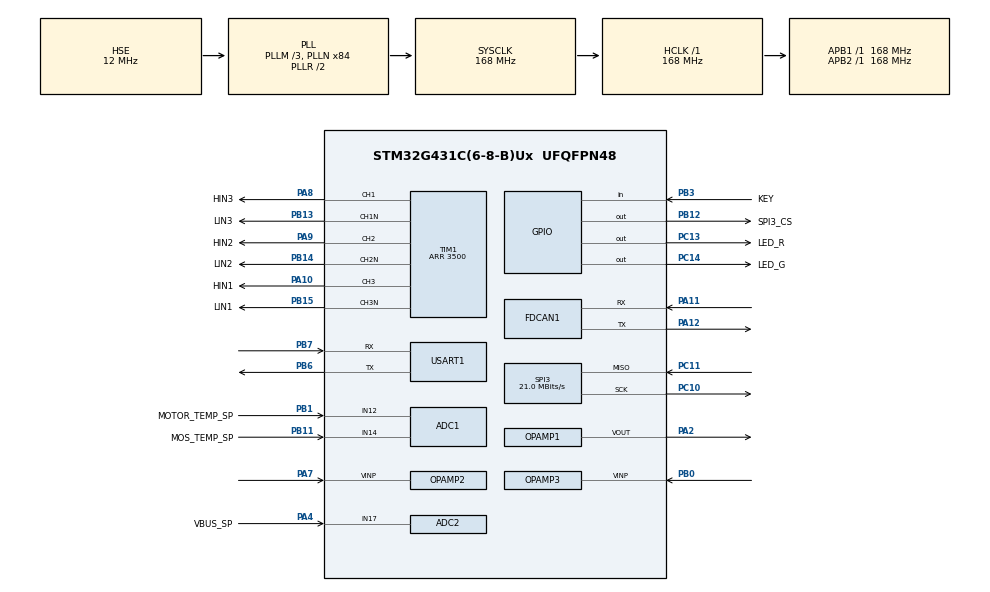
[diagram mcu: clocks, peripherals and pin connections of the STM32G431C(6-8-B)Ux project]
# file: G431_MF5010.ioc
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ADC1.Channel-0\#ChannelRegularConversion=ADC_CHANNEL_12
ADC1.Channel-1\#ChannelRegularConversion=ADC_CHANNEL_14
ADC1.NbrOfConversion=2
ADC1.NbrOfConversionFlag=1
ADC1.OffsetNumber-0\#ChannelRegularConversion=ADC_OFFSET_NONE
ADC1.OffsetNumber-1\#ChannelRegularConversion=ADC_OFFSET_NONE
ADC1.Rank-0\#ChannelRegularConversion=1
ADC1.Rank-1\#ChannelRegularConversion=2
ADC1.SamplingTime-0\#ChannelRegularConversion=ADC_SAMPLETIME_640CYCLES_5
ADC1.SamplingTime-1\#ChannelRegularConversion=ADC_SAMPLETIME_640CYCLES_5
ADC1.master=1
ADC2.ClockPrescaler=ADC_CLOCK_SYNC_PCLK_DIV4
ADC2.ContinuousConvMode=DISABLE
ADC2.EnableInjectedConversion=ENABLE
ADC2.EnableRegularConversion=DISABLE
ADC2.ExternalTrigInjecConv=ADC_EXTERNALTRIGINJEC_T1_CC4
ADC2.InjNumberOfConversion=3
ADC2.InjectedChannel-1\#ChannelInjectedConversion=ADC_CHANNEL_VOPAMP2
ADC2.InjectedChannel-2\#ChannelInjectedConversion=ADC_CHANNEL_VOPAMP3_ADC2
ADC2.InjectedChannel-3\#ChannelInjectedConversion=ADC_CHANNEL_17
ADC2.InjectedOffsetNumber-1\#ChannelInjectedConversion=ADC_OFFSET_NONE
ADC2.InjectedOffsetNumber-2\#ChannelInjectedConversion=ADC_OFFSET_NONE
ADC2.InjectedOffsetNumber-3\#ChannelInjectedConversion=ADC_OFFSET_NONE
ADC2.InjectedRank-1\#ChannelInjectedConversion=1
ADC2.InjectedRank-2\#ChannelInjectedConversion=2
ADC2.InjectedRank-3\#ChannelInjectedConversion=3
ADC2.InjectedSamplingTime-1\#ChannelInjectedConversion=ADC_SAMPLETIME_6CYCLES_5
ADC2.InjectedSamplingTime-2\#ChannelInjectedConversion=ADC_SAMPLETIME_6CYCLES_5
ADC2.InjectedSamplingTime-3\#ChannelInjectedConversion=ADC_SAMPLETIME_6CYCLES_5
Dma.ADC1.0.Direction=DMA_PERIPH_TO_MEMORY
Dma.ADC1.0.EventEnable=DISABLE
Dma.ADC1.0.Instance=DMA1_Channel1
Dma.ADC1.0.MemDataAlignment=DMA_MDATAALIGN_HALFWORD
Dma.ADC1.0.MemInc=DMA_MINC_ENABLE
Dma.ADC1.0.Mode=DMA_CIRCULAR
Dma.ADC1.0.PeriphDataAlignment=DMA_PDATAALIGN_HALFWORD
Dma.ADC1.0.PeriphInc=DMA_PINC_DISABLE
Dma.ADC1.0.Polarity=HAL_DMAMUX_REQ_GEN_RISING
Dma.ADC1.0.Priority=DMA_PRIORITY_LOW
Dma.ADC1.0.RequestNumber=1
Dma.ADC1.0.SignalID=NONE
Dma.ADC1.0.SyncEnable=DISABLE
Dma.ADC1.0.SyncPolarity=HAL_DMAMUX_SYNC_NO_EVENT
Dma.ADC1.0.SyncRequestNumber=1
Dma.ADC1.0.SyncSignalID=NONE
Dma.Request0=ADC1
FDCAN1.AutoRetransmission=DISABLE
FDCAN1.CalculateBaudRateNominal=1000000
FDCAN1.CalculateTimeBitNominal=1000
FDCAN1.CalculateTimeQuantumNominal=35.714285714285715
FDCAN1.DataPrescaler=6
FDCAN1.DataSyncJumpWidth=7
FDCAN1.DataTimeSeg1=20
FDCAN1.DataTimeSeg2=7
FDCAN1.ExtFiltersNbr=0
FDCAN1.NominalPrescaler=6
FDCAN1.NominalSyncJumpWidth=7
FDCAN1.NominalTimeSeg1=20
FDCAN1.NominalTimeSeg2=7
FDCAN1.StdFiltersNbr=1
Mcu.Family=STM32G4
Mcu.Name=STM32G431C(6-8-B)Ux
Mcu.Package=UFQFPN48
NVIC.ADC1_2_IRQn=true\:1\:0\:true\:false\:true\:true\:true\:true
NVIC.DMA1_Channel1_IRQn=true\:0\:0\:true\:false\:true\:false\:true\:true
NVIC.FDCAN1_IT0_IRQn=true\:0\:0\:true\:false\:true\:true\:true\:true
NVIC.PriorityGroup=NVIC_PRIORITYGROUP_4
NVIC.TIM4_IRQn=true\:0\:0\:true\:false\:true\:true\:true\:true
NVIC.TIM7_IRQn=true\:0\:0\:false\:false\:true\:true\:true\:true
NVIC.USART1_IRQn=true\:0\:0\:false\:false\:true\:true\:true\:true
OPAMP1.PowerMode=OPAMP_POWERMODE_HIGHSPEED
OPAMP2.PgaGain=OPAMP_PGA_GAIN_16_OR_MINUS_15
OPAMP2.PowerMode=OPAMP_POWERMODE_HIGHSPEED
OPAMP3.PgaGain=OPAMP_PGA_GAIN_16_OR_MINUS_15
OPAMP3.PowerMode=OPAMP_POWERMODE_HIGHSPEED
PA10.GPIO_Label=HIN1
PA10.Signal=S_TIM1_CH3
PA11.Mode=FDCAN_Activate
PA11.Signal=FDCAN1_RX
PA12.Mode=FDCAN_Activate
PA12.Signal=FDCAN1_TX
PA13.Mode=Serial_Wire
PA13.Signal=SYS_JTMS-SWDIO
PA14.Mode=Serial_Wire
PA14.Signal=SYS_JTCK-SWCLK
PA2.Mode=Follower-DAC_OUT2-INP
PA2.Signal=OPAMP1_VOUT
PA4.GPIO_Label=VBUS_SP
PA4.Mode=IN17-Single-Ended
PA4.Signal=ADC2_IN17
PA7.Mode=PGA_Internally_Connected
PA7.Signal=OPAMP2_VINP
PA8.GPIO_Label=HIN3
PA8.Signal=S_TIM1_CH1
PA9.GPIO_Label=HIN2
PA9.Signal=S_TIM1_CH2
PB0.Mode=PGA_Internally_Connected
PB0.Signal=OPAMP3_VINP
PB1.GPIO_Label=MOTOR_TEMP_SP
PB1.Mode=IN12-Single-Ended
PB1.Signal=ADC1_IN12
PB11.GPIO_Label=MOS_TEMP_SP
PB11.Mode=IN14-Single-Ended
PB11.Signal=ADC1_IN14
PB12.GPIO_Label=SPI3_CS
PB12.GPIO_ModeDefaultOutputPP=GPIO_MODE_OUTPUT_PP
PB12.GPIO_PuPd=GPIO_PULLUP
PB12.GPIO_Speed=GPIO_SPEED_FREQ_VERY_HIGH
PB12.PinState=GPIO_PIN_SET
PB12.Signal=GPIO_Output
PB13.GPIO_Label=LIN3
PB13.Mode=PWM Generation1 CH1 CH1N
PB13.Signal=TIM1_CH1N
PB14.GPIO_Label=LIN2
PB14.Mode=PWM Generation2 CH2 CH2N
PB14.Signal=TIM1_CH2N
PB15.GPIO_Label=LIN1
PB15.Mode=PWM Generation3 CH3 CH3N
PB15.Signal=TIM1_CH3N
PB3.GPIO_Label=KEY
PB3.GPIO_PuPd=GPIO_PULLUP
PB3.Signal=GPIO_Input
PB6.Mode=Asynchronous
PB6.Signal=USART1_TX
PB7.Mode=Asynchronous
PB7.Signal=USART1_RX
PC10.GPIO_PuPd=GPIO_PULLUP
PC10.GPIO_Speed=GPIO_SPEED_FREQ_VERY_HIGH
PC10.Mode=RX_Only_Simplex_Unidirect_Master
PC10.Signal=SPI3_SCK
PC11.GPIO_PuPd=GPIO_PULLUP
PC11.GPIO_Speed=GPIO_SPEED_FREQ_VERY_HIGH
PC11.Mode=RX_Only_Simplex_Unidirect_Master
PC11.Signal=SPI3_MISO
PC13.GPIO_Label=LED_R
PC13.Signal=GPIO_Output
PC14-OSC32_IN.GPIO_Label=LED_G
PC14-OSC32_IN.Signal=GPIO_Output
PF0-OSC_IN.Mode=HSE-External-Oscillator
PF0-OSC_IN.Signal=RCC_OSC_IN
PF1-OSC_OUT.Mode=HSE-External-Oscillator
PF1-OSC_OUT.Signal=RCC_OSC_OUT
ProjectManager.HeapSize=0x200
ProjectManager.StackSize=0x400
ProjectManager.TargetToolchain=STM32CubeIDE
RCC.ADC12Freq_Value=168000000
RCC.AHBFreq_Value=168000000
RCC.APB1Freq_Value=168000000
RCC.APB1TimFreq_Value=168000000
RCC.APB2Freq_Value=168000000
RCC.APB2TimFreq_Value=168000000
RCC.CK48CLockSelection=RCC_USBCLKSOURCE_HSI48
RCC.CortexFreq_Value=168000000
RCC.EXTERNAL_CLOCK_VALUE=12288000
RCC.HCLKFreq_Value=168000000
RCC.HSE_VALUE=12000000
RCC.HSI48_VALUE=48000000
RCC.HSI_VALUE=16000000
RCC.LSE_VALUE=32768
RCC.PLLM=RCC_PLLM_DIV3
RCC.PLLN=84
RCC.PLLSourceVirtual=RCC_PLLSOURCE_HSE
RCC.SYSCLKFreq_VALUE=168000000
RCC.SYSCLKSource=RCC_SYSCLKSOURCE_PLLCLK
RCC.USBFreq_Value=48000000
RCC.VCOOutputFreq_Value=336000000
SH.S_TIM1_CH1.0=TIM1_CH1,PWM Generation1 CH1 CH1N
SH.S_TIM1_CH2.0=TIM1_CH2,PWM Generation2 CH2 CH2N
SH.S_TIM1_CH3.0=TIM1_CH3,PWM Generation3 CH3 CH3N
SPI3.BaudRatePrescaler=SPI_BAUDRATEPRESCALER_8
SPI3.CLKPhase=SPI_PHASE_2EDGE
SPI3.CalculateBaudRate=21.0 MBits/s
SPI3.DataSize=SPI_DATASIZE_8BIT
SPI3.Direction=SPI_DIRECTION_2LINES_RXONLY
SPI3.Mode=SPI_MODE_MASTER
SPI3.VirtualType=VM_MASTER
STMicroelectronics.X-CUBE-ALGOBUILD.1.4.0.LibraryCcDSPOoLibraryJjDSPOoLibrary=true
TIM1.AutoReloadPreload=TIM_AUTORELOAD_PRELOAD_DISABLE
TIM1.BreakFilter=0
TIM1.BreakState=TIM_BREAK_ENABLE
TIM1.Channel-PWM\ Generation1\ CH1\ CH1N=TIM_CHANNEL_1
TIM1.Channel-PWM\ Generation2\ CH2\ CH2N=TIM_CHANNEL_2
TIM1.Channel-PWM\ Generation3\ CH3\ CH3N=TIM_CHANNEL_3
TIM1.Channel-PWM\ Generation4\ No\ Output=TIM_CHANNEL_4
TIM1.CounterMode=TIM_COUNTERMODE_CENTERALIGNED1
TIM1.DeadTime=20
TIM1.PeriodNoDither=3500
TIM1.PulseNoDither_4=3500-10
TIM1.TIM_MasterOutputTrigger=TIM_TRGO_OC4REF
TIM1.TIM_MasterOutputTrigger2=TIM_TRGO2_RESET
TIM1.TIM_MasterSlaveMode=TIM_MASTERSLAVEMODE_DISABLE
TIM4.PeriodNoDither=1000-1
TIM4.Prescaler=168-1
TIM7.PeriodNoDither=5000-1
TIM7.Prescaler=168-1
USART1.VirtualMode-Asynchronous=VM_ASYNC
VP_ADC2_OPAMP_INTERNAL2.Mode=IN-OPAMP2
VP_ADC2_OPAMP_INTERNAL3.Mode=IN-OPAMP3
VP_DAC3_VS_DACI1.Mode=DAC_OUT1_Int
VP_RNG_VS_RNG.Mode=RNG_Activate
VP_STMicroelectronics.X-CUBE-ALGOBUILD_VS_DSPOoLibraryJjLibrary_1.4.0_1.4.0.Mode=DSPOoLibraryJjLibrary
VP_SYS_VS_DBSignals.Mode=DisableDeadBatterySignals
VP_TIM1_VS_ClockSourceINT.Mode=Internal
VP_TIM1_VS_no_output4.Mode=PWM Generation4 No Output
VP_TIM4_VS_ClockSourceINT.Mode=Internal
VP_TIM7_VS_ClockSourceINT.Mode=Enable_Timer
board=custom

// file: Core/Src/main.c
/* USER CODE BEGIN Header */
/**
 ******************************************************************************
 * @file           : main.c
 * @brief          : Main program body
 ******************************************************************************
 * @attention
 *
 * Copyright (c) 2025 STMicroelectronics.
 * All rights reserved.
 *
 * This software is licensed under terms that can be found in the LICENSE file
 * in the root directory of this software component.
 * If no LICENSE file comes with this software, it is provided AS-IS.
 *
 ******************************************************************************
 */
/* USER CODE END Header */
#include "main.h"
#include "adc.h"
#include "dac.h"
#include "dma.h"
#include "fdcan.h"
#include "opamp.h"
#include "rng.h"
#include "spi.h"
#include "tim.h"
#include "usart.h"
#include "gpio.h"

/* USER CODE BEGIN Includes */
#include "motor.h"
/* USER CODE END Includes */

void SystemClock_Config(void);

int main(void)
{

  /* MCU Configuration--------------------------------------------------------*/

  /* Reset of all peripherals, Initializes the Flash interface and the Systick. */
  HAL_Init();

  /* Configure the system clock */
  SystemClock_Config();

  /* Initialize all configured peripherals */
  MX_GPIO_Init();
  MX_DMA_Init();
  MX_FDCAN1_Init();
  MX_OPAMP2_Init();
  MX_OPAMP3_Init();
  MX_TIM1_Init();
  MX_SPI3_Init();
  MX_ADC2_Init();
  MX_DAC3_Init();
  MX_OPAMP1_Init();
  MX_USART1_UART_Init();
  MX_ADC1_Init();
  MX_TIM4_Init();
  MX_TIM7_Init();
  MX_RNG_Init();
  /* USER CODE BEGIN 2 */
    MotorInit();
  /* USER CODE END 2 */

  /* Infinite loop */
  /* USER CODE BEGIN WHILE */

    while (1) {
        //   cpu_num++;
    /* USER CODE END WHILE */

    }
}

void SystemClock_Config(void)
{
  RCC_OscInitTypeDef RCC_OscInitStruct = {0};
  RCC_ClkInitTypeDef RCC_ClkInitStruct = {0};

  /** Configure the main internal regulator output voltage
  */
  HAL_PWREx_ControlVoltageScaling(PWR_REGULATOR_VOLTAGE_SCALE1_BOOST);

  /** Initializes the RCC Oscillators according to the specified parameters
  * in the RCC_OscInitTypeDef structure.
  */
  RCC_OscInitStruct.OscillatorType = RCC_OSCILLATORTYPE_HSI48|RCC_OSCILLATORTYPE_HSE;
  RCC_OscInitStruct.HSEState = RCC_HSE_ON;
  RCC_OscInitStruct.HSI48State = RCC_HSI48_ON;
  RCC_OscInitStruct.PLL.PLLState = RCC_PLL_ON;
  RCC_OscInitStruct.PLL.PLLSource = RCC_PLLSOURCE_HSE;
  RCC_OscInitStruct.PLL.PLLM = RCC_PLLM_DIV3;
  RCC_OscInitStruct.PLL.PLLN = 84;
  RCC_OscInitStruct.PLL.PLLP = RCC_PLLP_DIV2;
  RCC_OscInitStruct.PLL.PLLQ = RCC_PLLQ_DIV2;
  RCC_OscInitStruct.PLL.PLLR = RCC_PLLR_DIV2;
  if (HAL_RCC_OscConfig(&RCC_OscInitStruct) != HAL_OK)
  {
    Error_Handler();
  }

  /** Initializes the CPU, AHB and APB buses clocks
  */
  RCC_ClkInitStruct.ClockType = RCC_CLOCKTYPE_HCLK|RCC_CLOCKTYPE_SYSCLK
                              |RCC_CLOCKTYPE_PCLK1|RCC_CLOCKTYPE_PCLK2;
  RCC_ClkInitStruct.SYSCLKSource = RCC_SYSCLKSOURCE_PLLCLK;
  RCC_ClkInitStruct.AHBCLKDivider = RCC_SYSCLK_DIV1;
  RCC_ClkInitStruct.APB1CLKDivider = RCC_HCLK_DIV1;
  RCC_ClkInitStruct.APB2CLKDivider = RCC_HCLK_DIV1;

  if (HAL_RCC_ClockConfig(&RCC_ClkInitStruct, FLASH_LATENCY_4) != HAL_OK)
  {
    Error_Handler();
  }
}

void Error_Handler(void)
{
    __disable_irq();
    while (1) {
    }
}
